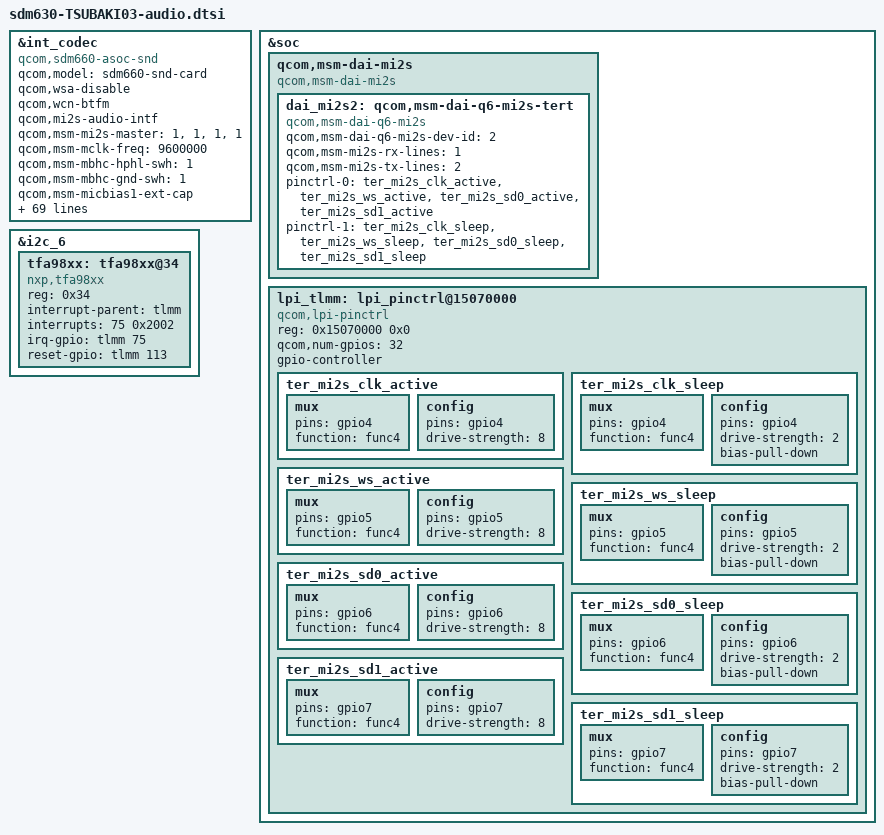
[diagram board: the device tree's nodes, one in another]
/*
 * This software is contributed or developed by KYOCERA Corporation.
 * (C) 2019 KYOCERA Corporation
 *
 * This program is free software; you can redistribute it and/or modify
 * it under the terms of the GNU General Public License version 2 and
 * only version 2 as published by the Free Software Foundation.
 *
 * This program is distributed in the hope that it will be useful,
 * but WITHOUT ANY WARRANTY; without even the implied warranty of
 * MERCHANTABILITY or FITNESS FOR A PARTICULAR PURPOSE.  See the
 * GNU General Public License for more details.
 */

&int_codec {
	status = "okay";
	compatible = "qcom,sdm660-asoc-snd";
	qcom,model = "sdm660-snd-card";
	qcom,wsa-disable;
	qcom,wcn-btfm;
	qcom,mi2s-audio-intf;
	/delete-property/ qcom,auxpcm-audio-intf;
	/delete-property/ qcom,ext-disp-audio-rx;
	qcom,msm-mi2s-master = <1>, <1>, <1>, <1>;
	qcom,msm-mclk-freq = <9600000>;
	qcom,msm-mbhc-hphl-swh = <1>;
	qcom,msm-mbhc-gnd-swh = <1>;
	qcom,msm-micbias1-ext-cap;
	/delete-property/ qcom,msm-micbias2-ext-cap;
	qcom,msm-hs-micbias-type = "internal";
	/delete-property/ qcom,us-euro-gpios;
	qcom,cdc-pdm-gpios = <&cdc_pdm_gpios>;
	qcom,cdc-comp-gpios = <&cdc_comp_gpios>;
	qcom,cdc-dmic-gpios = <&cdc_dmic_gpios>;
	kc,hs-detect-plug-time-ms = <1000>;
	kc,smart-amp;
	kc,usb-hs-type;
	kc,btn-low-th  = /bits/ 16 <112 200 337 337 337>;
	kc,btn-high-th = /bits/ 16 <112 200 337 337 337>;

	qcom,audio-routing =
		"RX_BIAS", "INT_MCLK0",
		"SPK_RX_BIAS", "INT_MCLK0",
		"INT_LDO_H", "INT_MCLK0",
		"MIC BIAS External", "Handset Mic",
		"MIC BIAS Internal2", "Headset Mic",
		"MIC BIAS External", "Secondary Mic",
		"AMIC1", "MIC BIAS External",
		"AMIC2", "MIC BIAS Internal2",
		"AMIC3", "MIC BIAS External",
		"PDM_IN_RX1", "PDM_OUT_RX1",
		"PDM_IN_RX2", "PDM_OUT_RX2",
		"PDM_IN_RX3", "PDM_OUT_RX3",
		"ADC1_IN", "ADC1_OUT",
		"ADC2_IN", "ADC2_OUT",
		"ADC3_IN", "ADC3_OUT";
	asoc-platform = <&pcm0>, <&pcm1>, <&pcm2>, <&voip>, <&voice>,
			<&loopback>, <&compress>, <&hostless>,
			<&afe>, <&lsm>, <&routing>, <&compr>,
			<&pcm_noirq>;
	asoc-platform-names = "msm-pcm-dsp.0", "msm-pcm-dsp.1",
			"msm-pcm-dsp.2", "msm-voip-dsp",
			"msm-pcm-voice", "msm-pcm-loopback",
			"msm-compress-dsp", "msm-pcm-hostless",
			"msm-pcm-afe", "msm-lsm-client",
			"msm-pcm-routing", "msm-compr-dsp",
			"msm-pcm-dsp-noirq";
	asoc-cpu = <&dai_dp>, <&dai_mi2s0>,
			<&dai_mi2s1>,
			<&dai_mi2s2>, <&dai_mi2s3>,
			<&dai_int_mi2s0>, <&dai_int_mi2s1>,
			<&dai_int_mi2s2>, <&dai_int_mi2s3>,
			<&dai_int_mi2s4>, <&dai_int_mi2s5>,
			<&dai_pri_auxpcm>, <&dai_sec_auxpcm>,
			<&dai_tert_auxpcm>, <&dai_quat_auxpcm>,
			<&afe_pcm_rx>, <&afe_pcm_tx>, <&afe_proxy_rx>,
			<&afe_proxy_tx>, <&incall_record_rx>,
			<&incall_record_tx>, <&incall_music_rx>,
			<&incall_music_2_rx>, <&sb_7_rx>, <&sb_7_tx>,
			<&sb_8_tx>, <&sb_8_rx>,
			<&usb_audio_rx>, <&usb_audio_tx>,
			<&dai_pri_tdm_rx_0>, <&dai_pri_tdm_tx_0>,
			<&dai_sec_tdm_rx_0>, <&dai_sec_tdm_tx_0>,
			<&dai_tert_tdm_rx_0>, <&dai_tert_tdm_tx_0>,
			<&dai_quat_tdm_rx_0>, <&dai_quat_tdm_tx_0>;
	asoc-cpu-names = "msm-dai-q6-dp.24608", "msm-dai-q6-mi2s.0",
			"msm-dai-q6-mi2s.1",
			"msm-dai-q6-mi2s.2", "msm-dai-q6-mi2s.3",
			"msm-dai-q6-mi2s.7", "msm-dai-q6-mi2s.8",
			"msm-dai-q6-mi2s.9", "msm-dai-q6-mi2s.10",
			"msm-dai-q6-mi2s.11", "msm-dai-q6-mi2s.12",
			"msm-dai-q6-auxpcm.1", "msm-dai-q6-auxpcm.2",
			"msm-dai-q6-auxpcm.3", "msm-dai-q6-auxpcm.4",
			"msm-dai-q6-dev.224", "msm-dai-q6-dev.225",
			"msm-dai-q6-dev.241", "msm-dai-q6-dev.240",
			"msm-dai-q6-dev.32771", "msm-dai-q6-dev.32772",
			"msm-dai-q6-dev.32773", "msm-dai-q6-dev.32770",
			"msm-dai-q6-dev.16398", "msm-dai-q6-dev.16399",
			"msm-dai-q6-dev.16401", "msm-dai-q6-dev.16400",
			"msm-dai-q6-dev.28672", "msm-dai-q6-dev.28673",
			"msm-dai-q6-tdm.36864", "msm-dai-q6-tdm.36865",
			"msm-dai-q6-tdm.36880", "msm-dai-q6-tdm.36881",
			"msm-dai-q6-tdm.36896", "msm-dai-q6-tdm.36897",
			"msm-dai-q6-tdm.36912", "msm-dai-q6-tdm.36913";
	asoc-codec = <&stub_codec>, <&msm_digital_codec>,
			<&pmic_analog_codec>;
	asoc-codec-names = "msm-stub-codec.1", "msm-dig-codec",
				"analog-codec";
	/delete-property/ qcom,wsa-max-devs;
	/delete-property/ qcom,wsa-devs;
	/delete-property/ qcom,wsa-aux-dev-prefix;
};

&soc {
	qcom,msm-dai-mi2s {
		compatible = "qcom,msm-dai-mi2s";

		dai_mi2s2: qcom,msm-dai-q6-mi2s-tert {
			compatible = "qcom,msm-dai-q6-mi2s";
			qcom,msm-dai-q6-mi2s-dev-id = <2>;
			qcom,msm-mi2s-rx-lines = <1>;
			qcom,msm-mi2s-tx-lines = <2>;
			pinctrl-names = "default","sleep";
			pinctrl-0 = <&ter_mi2s_clk_active &ter_mi2s_ws_active
				&ter_mi2s_sd0_active &ter_mi2s_sd1_active>;
			pinctrl-1 = <&ter_mi2s_clk_sleep &ter_mi2s_ws_sleep
				&ter_mi2s_sd0_sleep &ter_mi2s_sd1_sleep>;
		};
	};

	lpi_tlmm: lpi_pinctrl@15070000 {
		compatible = "qcom,lpi-pinctrl";
		reg = <0x15070000 0x0>;
		qcom,num-gpios = <32>;
		gpio-controller;
		#gpio-cells = <2>;

		ter_mi2s_clk_active: ter_mi2s_clk_active {
			mux {
				pins = "gpio4";
				function = "func4";
			};

			config {
				pins = "gpio4";
				drive-strength = <8>;
			};
		};

		ter_mi2s_clk_sleep: ter_mi2s_clk_sleep {
			mux {
				pins = "gpio4";
				function = "func4";
			};

			config {
				pins = "gpio4";
				drive-strength = <2>;
				bias-pull-down;
			};
		};

		ter_mi2s_ws_active: ter_mi2s_ws_active {
			mux {
				pins = "gpio5";
				function = "func4";
			};

			config {
				pins = "gpio5";
				drive-strength = <8>;
			};
		};

		ter_mi2s_ws_sleep: ter_mi2s_ws_sleep {
			mux {
				pins = "gpio5";
				function = "func4";
			};

			config {
				pins = "gpio5";
				drive-strength = <2>;
				bias-pull-down;
			};
		};
		ter_mi2s_sd0_active: ter_mi2s_sd0_active {
			mux {
				pins = "gpio6";
				function = "func4";
			};

			config {
				pins = "gpio6";
				drive-strength = <8>;
			};
		};

		ter_mi2s_sd0_sleep: ter_mi2s_sd0_sleep {
			mux {
				pins = "gpio6";
				function = "func4";
			};

			config {
				pins = "gpio6";
				drive-strength = <2>;
				bias-pull-down;
			};
		};
		ter_mi2s_sd1_active: ter_mi2s_sd1_active {
			mux {
				pins = "gpio7";
				function = "func4";
			};

			config {
				pins = "gpio7";
				drive-strength = <8>;
			};
		};

		ter_mi2s_sd1_sleep: ter_mi2s_sd1_sleep {
			mux {
				pins = "gpio7";
				function = "func4";
			};

			config {
				pins = "gpio7";
				drive-strength = <2>;
				bias-pull-down;
			};
		};
	};
};

&i2c_6 { /* BLSP1 QUP6 (NFC) */
	status = "okay";
	tfa98xx: tfa98xx@34 {
		compatible = "nxp,tfa98xx";
		reg = <0x34>;
		interrupt-parent = <&tlmm>;
		interrupts = <75 0x2002>;
		irq-gpio = <&tlmm 75 0x2008>;
		reset-gpio = <&tlmm 113 0x00>;
	};
};
